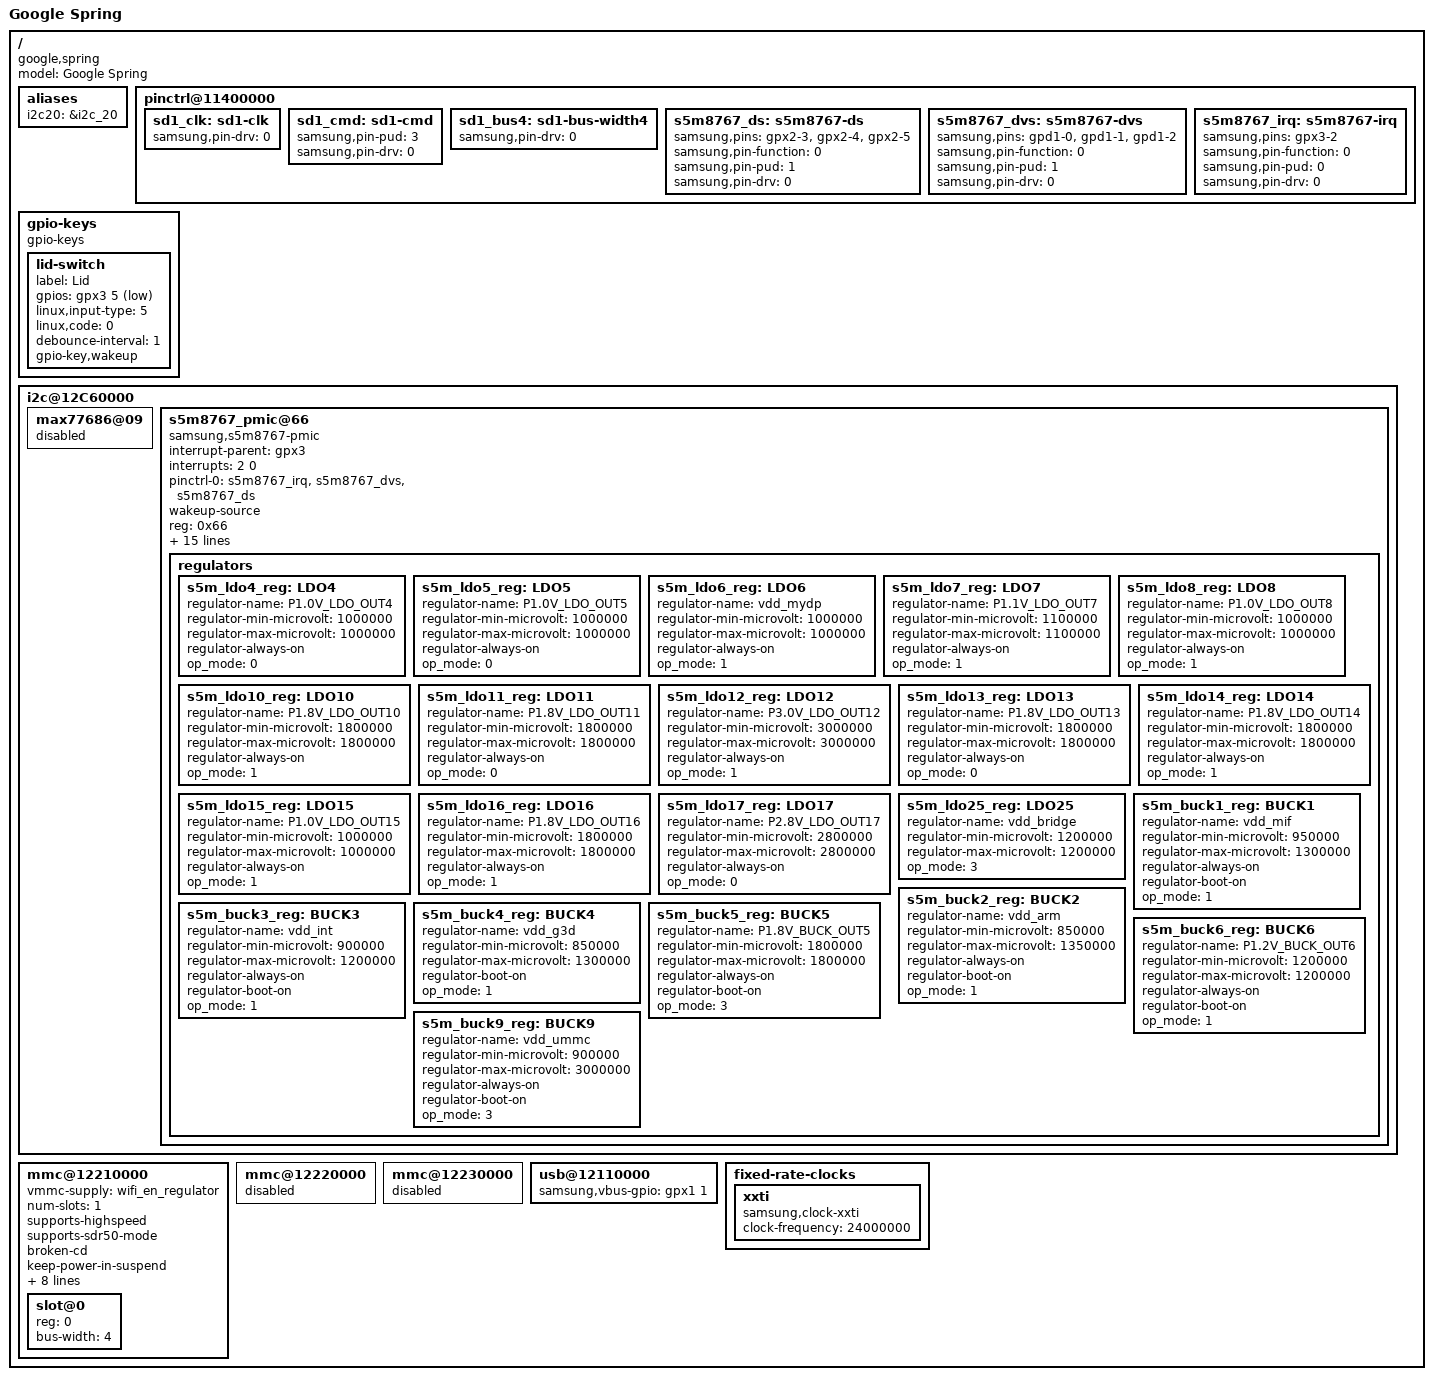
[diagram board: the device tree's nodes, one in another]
/*
 * Google Snow board device tree source
 *
 * Copyright (c) 2012 Google, Inc
 *
 * This program is free software; you can redistribute it and/or modify
 * it under the terms of the GNU General Public License version 2 as
 * published by the Free Software Foundation.
*/

/dts-v1/;
#include "exynos5250.dtsi"
#include "exynos5250-cros-common.dtsi"

/ {
	model = "Google Spring";
	compatible = "google,spring", "samsung,exynos5250";

	aliases {
		i2c20 = &i2c_20;
	};

	pinctrl@11400000 {
		sd1_clk: sd1-clk {
			samsung,pin-drv = <0>;
		};

		sd1_cmd: sd1-cmd {
			samsung,pin-pud = <3>;
			samsung,pin-drv = <0>;
		};

		sd1_bus4: sd1-bus-width4 {
			samsung,pin-drv = <0>;
		};

		s5m8767_ds: s5m8767-ds {
			samsung,pins = "gpx2-3", "gpx2-4", "gpx2-5";
			samsung,pin-function = <0>;
			samsung,pin-pud = <1>;
			samsung,pin-drv = <0>;
		};

		s5m8767_dvs: s5m8767-dvs {
			samsung,pins = "gpd1-0", "gpd1-1", "gpd1-2";
			samsung,pin-function = <0>;
			samsung,pin-pud = <1>;
			samsung,pin-drv = <0>;
		};

		s5m8767_irq: s5m8767-irq {
			samsung,pins = "gpx3-2";
			samsung,pin-function = <0>;
			samsung,pin-pud = <0>;
			samsung,pin-drv = <0>;
		};
	};

	gpio-keys {
		compatible = "gpio-keys";

		lid-switch {
			label = "Lid";
			gpios = <&gpx3 5 1>;
			linux,input-type = <5>; /* EV_SW */
			linux,code = <0>; /* SW_LID */
			debounce-interval = <1>;
			gpio-key,wakeup;
		};
	};

	i2c@12C60000 {
		max77686@09 {
			status = "disabled";
		};

		s5m8767_pmic@66 {
			compatible = "samsung,s5m8767-pmic";
			interrupt-parent = <&gpx3>;
			interrupts = <2 0>;
			pinctrl-names = "default";
			pinctrl-0 = <&s5m8767_irq &s5m8767_dvs &s5m8767_ds>;
			wakeup-source;
			reg = <0x66>;

			s5m-core,enable-low-jitter;
			s5m-core,device_type = <2>;

			s5m8767,pmic-buck-dvs-gpios = <&gpd1 0 1>, /* DVS1 */
			                              <&gpd1 1 1>, /* DVS2 */
			                              <&gpd1 2 1>; /* DVS3 */

			s5m8767,pmic-buck-ds-gpios = <&gpx2 3 1>, /* SET1 */
			                             <&gpx2 4 1>, /* SET2 */
			                             <&gpx2 5 1>; /* SET3 */

			/*
			 * The following arrays of DVS voltages are not used, since we are
			 * not using GPIOs to control PMIC bucks, but they must be defined
			 * to please the driver.
			 */
			s5m8767,pmic-buck2-dvs-voltage = <1350000>, <1300000>,
			                                 <1250000>, <1200000>,
			                                 <1150000>, <1100000>,
			                                 <1000000>, <950000>;

			s5m8767,pmic-buck3-dvs-voltage = <1100000>, <1100000>,
			                                 <1100000>, <1100000>,
			                                 <1000000>, <1000000>,
			                                 <1000000>, <1000000>;

			s5m8767,pmic-buck4-dvs-voltage = <1200000>, <1200000>,
			                                 <1200000>, <1200000>,
			                                 <1200000>, <1200000>,
			                                 <1200000>, <1200000>;

			regulators {
				s5m_ldo4_reg: LDO4 {
					regulator-name = "P1.0V_LDO_OUT4";
					regulator-min-microvolt = <1000000>;
					regulator-max-microvolt = <1000000>;
					regulator-always-on;
					/* Output OFF */
					op_mode = <0>;
				};

				s5m_ldo5_reg: LDO5 {
					regulator-name = "P1.0V_LDO_OUT5";
					regulator-min-microvolt = <1000000>;
					regulator-max-microvolt = <1000000>;
					regulator-always-on;
					/* Output OFF */
					op_mode = <0>;
				};

				s5m_ldo6_reg: LDO6 {
					regulator-name = "vdd_mydp";
					regulator-min-microvolt = <1000000>;
					regulator-max-microvolt = <1000000>;
					regulator-always-on;
					/* Output ON/OFF controlled by PWRREQ */
					op_mode = <1>;
				};

				s5m_ldo7_reg: LDO7 {
					regulator-name = "P1.1V_LDO_OUT7";
					regulator-min-microvolt = <1100000>;
					regulator-max-microvolt = <1100000>;
					regulator-always-on;
					/* Output ON/OFF controlled by PWRREQ */
					op_mode = <1>;
				};

				s5m_ldo8_reg: LDO8 {
					regulator-name = "P1.0V_LDO_OUT8";
					regulator-min-microvolt = <1000000>;
					regulator-max-microvolt = <1000000>;
					regulator-always-on;
					/* Output ON/OFF controlled by PWRREQ */
					op_mode = <1>;
				};

				s5m_ldo10_reg: LDO10 {
					regulator-name = "P1.8V_LDO_OUT10";
					regulator-min-microvolt = <1800000>;
					regulator-max-microvolt = <1800000>;
					regulator-always-on;
					/* Output ON/OFF controlled by PWRREQ */
					op_mode = <1>;
				};

				s5m_ldo11_reg: LDO11 {
					regulator-name = "P1.8V_LDO_OUT11";
					regulator-min-microvolt = <1800000>;
					regulator-max-microvolt = <1800000>;
					regulator-always-on;
					/* Output OFF */
					op_mode = <0>;
				};

				s5m_ldo12_reg: LDO12 {
					regulator-name = "P3.0V_LDO_OUT12";
					regulator-min-microvolt = <3000000>;
					regulator-max-microvolt = <3000000>;
					regulator-always-on;
					/* Output ON/OFF controlled by PWRREQ */
					op_mode = <1>;
				};

				s5m_ldo13_reg: LDO13 {
					regulator-name = "P1.8V_LDO_OUT13";
					regulator-min-microvolt = <1800000>;
					regulator-max-microvolt = <1800000>;
					regulator-always-on;
					/* Output OFF */
					op_mode = <0>;
				};

				s5m_ldo14_reg: LDO14 {
					regulator-name = "P1.8V_LDO_OUT14";
					regulator-min-microvolt = <1800000>;
					regulator-max-microvolt = <1800000>;
					regulator-always-on;
					/* Output ON/OFF controlled by PWRREQ */
					op_mode = <1>;
				};

				s5m_ldo15_reg: LDO15 {
					regulator-name = "P1.0V_LDO_OUT15";
					regulator-min-microvolt = <1000000>;
					regulator-max-microvolt = <1000000>;
					regulator-always-on;
					/* Output ON/OFF controlled by PWRREQ */
					op_mode = <1>;
				};

				s5m_ldo16_reg: LDO16 {
					regulator-name = "P1.8V_LDO_OUT16";
					regulator-min-microvolt = <1800000>;
					regulator-max-microvolt = <1800000>;
					regulator-always-on;
					/* Output ON/OFF controlled by PWRREQ */
					op_mode = <1>;
				};

				s5m_ldo17_reg: LDO17 {
					regulator-name = "P2.8V_LDO_OUT17";
					regulator-min-microvolt = <2800000>;
					regulator-max-microvolt = <2800000>;
					regulator-always-on;
					/* Output OFF */
					op_mode = <0>;
				};

				s5m_ldo25_reg: LDO25 {
					regulator-name = "vdd_bridge";
					regulator-min-microvolt = <1200000>;
					regulator-max-microvolt = <1200000>;
					/* Output ON */
					op_mode = <3>;
				};

				s5m_buck1_reg: BUCK1 {
					regulator-name = "vdd_mif";
					regulator-min-microvolt = <950000>;
					regulator-max-microvolt = <1300000>;
					regulator-always-on;
					regulator-boot-on;
					/* Output ON/OFF controlled by PWRREQ */
					op_mode = <1>;
				};

				s5m_buck2_reg: BUCK2 {
					regulator-name = "vdd_arm";
					regulator-min-microvolt = <850000>;
					regulator-max-microvolt = <1350000>;
					regulator-always-on;
					regulator-boot-on;
					/* Output ON/OFF controlled by PWRREQ */
					op_mode = <1>;
				};

				s5m_buck3_reg: BUCK3 {
					regulator-name = "vdd_int";
					regulator-min-microvolt = <900000>;
					regulator-max-microvolt = <1200000>;
					regulator-always-on;
					regulator-boot-on;
					/* Output ON/OFF controlled by PWRREQ */
					op_mode = <1>;
				};

				s5m_buck4_reg: BUCK4 {
					regulator-name = "vdd_g3d";
					regulator-min-microvolt = <850000>;
					regulator-max-microvolt = <1300000>;
					regulator-boot-on;
					/* Output ON/OFF controlled by PWRREQ */
					op_mode = <1>;
				};

				s5m_buck5_reg: BUCK5 {
					regulator-name = "P1.8V_BUCK_OUT5";
					regulator-min-microvolt = <1800000>;
					regulator-max-microvolt = <1800000>;
					regulator-always-on;
					regulator-boot-on;
					/* Output ON */
					op_mode = <3>;
				};

				s5m_buck6_reg: BUCK6 {
					regulator-name = "P1.2V_BUCK_OUT6";
					regulator-min-microvolt = <1200000>;
					regulator-max-microvolt = <1200000>;
					regulator-always-on;
					regulator-boot-on;
					/* Output OFF */
					op_mode = <1>;
				};

				s5m_buck9_reg: BUCK9 {
					regulator-name = "vdd_ummc";
					regulator-min-microvolt = <900000>;
					regulator-max-microvolt = <3000000>;
					regulator-always-on;
					regulator-boot-on;
					/* Output ON/OFF controlled by PWRREQ */
					op_mode = <3>;
				};
			};
		};
	};

	mmc@12210000 {
		status = "okay";
		
		/*
		 * The current best way to guarantee that reset/enable and clocks are
		 * available before we try to probe the WiFi card is through a chain of
		 * regulators.
		 */
		vmmc-supply = <&wifi_en_regulator>;

		num-slots = <1>;
		supports-highspeed;
		supports-sdr50-mode;
		broken-cd;
		keep-power-in-suspend;
		edge-triggered-interrupts;
		fifo-depth = <0x80>;
		card-detect-delay = <200>;
		clock-frequency = <80000000>;
		samsung,dw-mshc-ciu-div = <3>;
		samsung,dw-mshc-sdr-timing = <2 3>;
		samsung,dw-mshc-ddr-timing = <1 2>;

		/*
		 * WiFi is a SiP, so we can keep drive strength low to reduce EMI.
		 */
		pinctrl-names = "default";
		pinctrl-0 = <&sd1_clk &sd1_cmd &sd1_bus4>;

		slot@0 {
			reg = <0>;
			bus-width = <4>;
		};
	};

	mmc@12220000 {
		/* MMC2 pins are used as GPIO for eDP bridge control. */
		status = "disabled";
	};

	mmc@12230000 {
		/* Nothing is connected on MMC3, disable it.
		 *
		 * Overrides the default configuration for this port, which is to
		 * configure it for SDIO, as noted in cros5250-common.dtsi.
		 */
		status = "disabled";
	};

	usb@12110000 {
		samsung,vbus-gpio = <&gpx1 1 0>;
	};

	fixed-rate-clocks {
		xxti {
			compatible = "samsung,clock-xxti";
			clock-frequency = <24000000>;
		};
	};
};

